VERSION ""

NS_ :

BS_:

BU_: HMI_System CAVs_System

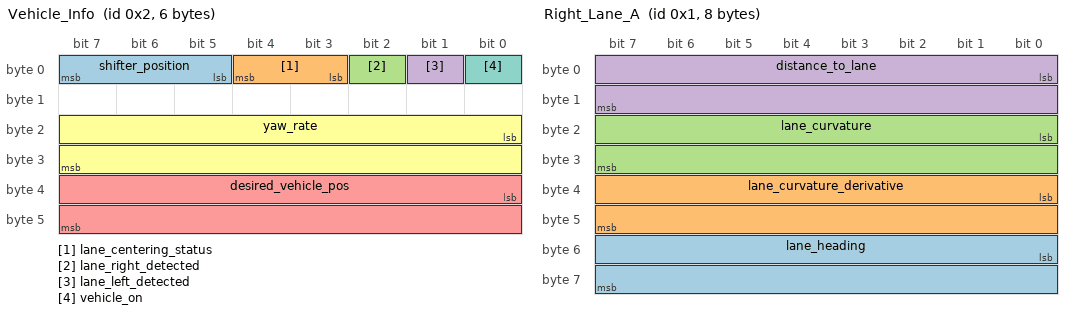
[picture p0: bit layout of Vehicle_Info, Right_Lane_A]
BO_ 2 Vehicle_Info: 6 Vector__XXX
 SG_ shifter_position : 5|3@1+ (1,0) [0|7] "" Vector__XXX
 SG_ lane_centering_status : 3|2@1+ (1,0) [0|3] "" Vector__XXX
 SG_ lane_right_detected : 2|1@1+ (1,0) [0|1] "" Vector__XXX
 SG_ lane_left_detected : 1|1@1+ (1,0) [0|1] "" Vector__XXX
 SG_ desired_vehicle_pos : 32|16@1- (0.00390625,0) [-127|128] "" Vector__XXX
 SG_ yaw_rate : 16|16@1- (0.00549316406,0) [-180|180] "" Vector__XXX
 SG_ vehicle_on : 0|1@1+ (1,0) [0|1] "" Vector__XXX

BO_ 1 Right_Lane_A: 8 Vector__XXX
 SG_ lane_heading : 48|16@1- (0.0009765625,0) [-0.357|0.357] "radians" Vector__XXX
 SG_ lane_curvature_derivative : 32|16@1- (3.72529029846191E-009,0) [-0.00012|0.00012] "1/m^2" Vector__XXX
 SG_ lane_curvature : 16|16@1- (9.765625E-007,0) [-0.02|0.02] "1/m" Vector__XXX
 SG_ distance_to_lane : 0|16@1- (0.00390625,0) [-127|128] "meter" Vector__XXX

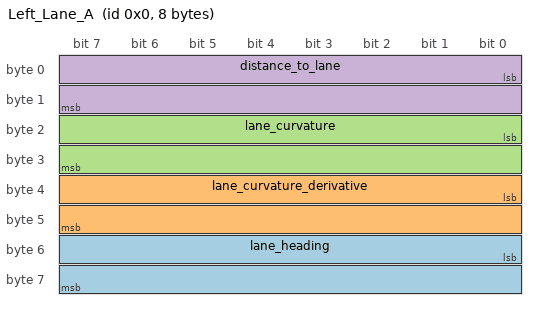
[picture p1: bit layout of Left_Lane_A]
BO_ 0 Left_Lane_A: 8 CAVs_System
 SG_ lane_heading : 48|16@1- (0.0009765625,0) [-0.357|0.357] "radians" Vector__XXX
 SG_ lane_curvature_derivative : 32|16@1- (3.72529029846191E-009,0) [-0.00012|0.00012] "1/m^2" Vector__XXX
 SG_ lane_curvature : 16|16@1- (9.765625E-007,0) [-0.02|0.02] "1/m" Vector__XXX
 SG_ distance_to_lane : 0|16@1- (0.00390625,0) [-127|128] "meter" Vector__XXX

BA_DEF_  "BusType" STRING ;
BA_DEF_DEF_  "BusType" "";
BA_ "BusType" "CAN";
